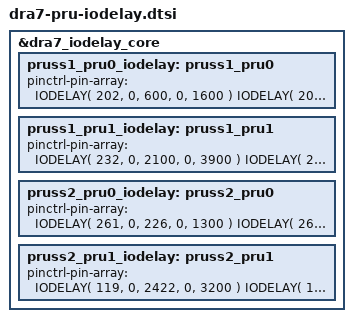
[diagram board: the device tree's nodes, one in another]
#define IODELAY_IN( index, a_delay, g_delay ) \
    ( 12 * (index) + 0 )   A_DELAY_PS( a_delay )   G_DELAY_PS( g_delay )
#define IODELAY_OUT( index, a_delay, g_delay ) \
    ( 12 * (index) + 4 )   A_DELAY_PS( a_delay )   G_DELAY_PS( g_delay ) \
    ( 12 * (index) + 8 )   A_DELAY_PS( a_delay )   G_DELAY_PS( g_delay )
#define IODELAY( index, in_a_delay, in_g_delay, out_a_delay, out_g_delay ) \
    IODELAY_IN( index, in_a_delay, in_g_delay ) \
    IODELAY_OUT( index, out_a_delay, out_g_delay )

&dra7_iodelay_core {
    pruss1_pru0_iodelay: pruss1_pru0 {
        pinctrl-pin-array = <
            IODELAY( 202, 0, 600, 0, 1600 ) // P19.52 AH6 core 0 gpio 0
            IODELAY( 203, 0, 0,   0, 2800 ) // P19.45 AH3 core 0 gpio 1
            IODELAY( 204, 0, 900, 0, 0    ) // P19.48 AH5 core 0 gpio 2
            IODELAY( 205, 0, 400, 0, 0    ) // P19.53 AH6 core 0 gpio 3
            IODELAY( 206, 0, 500, 0, 0    ) // P19.14 AH4 core 0 gpio 4
            IODELAY( 207, 0, 0,   0, 0    ) // P19.15 AG4 core 0 gpio 5
            IODELAY( 208, 0, 0,   0, 0    ) // x      AG2 core 0 gpio 6
            IODELAY( 186, 0, 0,   0, 600  ) // P19.46 AG3 core 0 gpio 7
            IODELAY( 187, 0, 300, 0, 0    ) // P19.49 AG5 core 0 gpio 8
            IODELAY( 188, 0, 800, 0, 2700 ) // P19.42 AF2 core 0 gpio 9
            IODELAY( 189, 0,   0, 0, 200  ) // x      AF6 core 0 gpio 10
            IODELAY( 190, 0, 600, 0, 800  ) // P19.43 AF3 core 0 gpio 11
            IODELAY( 191, 0,1100, 0, 0    ) // x      AF4 core 0 gpio 12
            IODELAY( 192, 0, 800, 0, 100  ) // P19.11 AF1 core 0 gpio 13
            IODELAY( 193, 0,1000, 0, 300  ) // x      AE3 core 0 gpio 14
            IODELAY( 194, 0,1100, 0, 0    ) // x      AE5 core 0 gpio 15
            IODELAY( 195, 0,2800, 0, 400  ) // P19.39 AE1 core 0 gpio 16
            IODELAY( 197, 0, 900, 0, 300  ) // P19.12 AE2 core 0 gpio 17
            IODELAY( 198, 0, 800, 0, 500  ) // x      AE6 core 0 gpio 18
            IODELAY( 199, 0,1400, 0, 0    ) // P19.40 AD2 core 0 gpio 19
            IODELAY( 200, 0,1001, 0, 500  ) // x      AD3 core 0 gpio 20
        >;
    };

    pruss1_pru1_iodelay: pruss1_pru1 {
        pinctrl-pin-array = <
            IODELAY( 232, 0, 2100, 0, 3900 ) // P18.42 E2 core 1 gpio 0
            IODELAY( 233, 0, 1000, 0, 5100 ) // P18.13 D2 core 1 gpio 1
            IODELAY( 234, 0, 1700, 0,    0 ) // P18.08 F4 core 1 gpio 2
            IODELAY( 235, 0, 700,  0, 2700 ) // P18.43 C1 core 1 gpio 3
            IODELAY( 236, 0, 1300, 0, 2600 ) // P18.39 E4 core 1 gpio 4
            IODELAY( 237, 0, 1700, 0, 2500 ) // P18.38 F5 core 1 gpio 5
            IODELAY( 238, 0, 1600, 0, 1900 ) // P18.07 E6 core 1 gpio 6
            IODELAY( 216, 0, 1600, 0, 1900 ) // P18.44 D3 core 1 gpio 7
            IODELAY( 217, 0, 1000, 0, 2700 ) // P18.06 F6 core 1 gpio 8
            IODELAY( 218, 0, 1400, 0, 3400 ) // eth1   D5 core 1 gpio 9
            IODELAY( 219, 0, 800,  0, 3200 ) // eth1   C2 core 1 gpio 10
            IODELAY( 220, 0, 0,    0, 3000 ) // eth1   C3 core 1 gpio 11
            IODELAY( 221, 0, 1600, 0, 2900 ) // eth1   C4 core 1 gpio 12
            IODELAY( 222, 0, 1200, 0, 2700 ) // eth1   B2 core 1 gpio 13
            IODELAY( 223, 0, 1500, 0, 3000 ) // eth1   D6 core 1 gpio 14
            IODELAY( 224, 0, 1000, 0, 2200 ) // eth1   C5 core 1 gpio 15
            IODELAY( 225, 0, 1100, 0, 2300 ) // eth1   A3 core 1 gpio 16
            IODELAY( 227, 0, 700,  0, 1800 ) // eth1   B3 core 1 gpio 17
            IODELAY( 228, 0, 1300, 0, 1900 ) // eth1   B4 core 1 gpio 18
            IODELAY( 229, 0, 1400, 0, 1400 ) // eth1   B5 core 1 gpio 19
            IODELAY( 230, 0, 1300, 0, 1900 ) // eth1   A4 core 1 gpio 20
        >;
    };

    pruss2_pru0_iodelay: pruss2_pru0 {
        pinctrl-pin-array = <
            IODELAY( 261, 0,  226, 0, 1300 ) // P18.26  G11 core 0 gpio 0
            IODELAY( 262, 0,    0, 0, 2500 ) // P18.48  E09 core 0 gpio 1
            IODELAY( 263, 0,  365, 0,  950 ) // P18.49  F09 core 0 gpio 2
            IODELAY( 264, 0,    0, 0,  800 ) // P18.45  F08 core 0 gpio 3
            IODELAY( 265, 0,  218, 0,  600 ) // P18.46  E07 core 0 gpio 4
            IODELAY( 266, 0,  186, 0,  500 ) // P18.47  E08 core 0 gpio 5
            IODELAY( 267, 0,  308, 0,  500 ) // P18.56  D09 core 0 gpio 6
            IODELAY( 245, 0,    0, 0,    0 ) // P18.16  D07 core 0 gpio 7
            IODELAY( 246, 0,  756, 0,  600 ) // P18.18  D08 core 0 gpio 8
            IODELAY( 247, 0,  531, 0, 2300 ) // P18.20  A05 core 0 gpio 9
            IODELAY( 248, 0,  180, 0,  450 ) // P18.15  C06 core 0 gpio 10
            IODELAY( 249, 0,  334, 0,  600 ) // P18.17  C08 core 0 gpio 11
            IODELAY( 250, 0, 1361, 0,  500 ) // P18.14  C07 core 0 gpio 12
            IODELAY( 251, 0,  488, 0,  100 ) // P18.50  B07 core 0 gpio 13
            IODELAY( 252, 0,  321, 0,  300 ) // P18.51  B08 core 0 gpio 14
            IODELAY( 253, 0,  254, 0,  700 ) // P18.21  A07 core 0 gpio 15
            IODELAY( 254, 0,  500, 0,  700 ) // P18.22  A08 core 0 gpio 16
            IODELAY( 256, 0,  716, 0,  900 ) // P18.19  C09 core 0 gpio 17
            IODELAY( 257, 0,    0, 0,  900 ) // P18.23  A09 core 0 gpio 18
            IODELAY( 258, 0,  404, 0,  300 ) // P18.52  B09 core 0 gpio 19
            IODELAY( 259, 0,  290, 0,  300 ) // P18.24  A10 core 0 gpio 20
        >;
    };

    pruss2_pru1_iodelay: pruss2_pru1 {
        pinctrl-pin-array = <
            IODELAY( 119, 0, 2422, 0, 3200 ) // ethmdio V01 core 1 gpio 0
            IODELAY( 118, 0, 3200, 0, 3900 ) // ethmdio U04 core 1 gpio 1
            IODELAY(   0, 0, 2100, 0, 2500 ) // x       U03 core 1 gpio 2
            IODELAY( 180, 0, 1900, 0, 3400 ) // P18.59  V02 core 1 gpio 3
            IODELAY( 181, 0, 1900, 0, 3000 ) // P18.29  Y01 core 1 gpio 4
            IODELAY( 150, 0, 2488, 0, 3300 ) // eth0    W09 core 1 gpio 5
            IODELAY( 151, 0, 2263, 0, 2700 ) // eth0    V09 core 1 gpio 6
            IODELAY( 155, 0, 2400, 0, 3200 ) // eth0    V07 core 1 gpio 7
            IODELAY( 154, 0, 2800, 0, 3000 ) // eth0    U07 core 1 gpio 8
            IODELAY( 153, 0, 2900, 0, 2500 ) // eth0    V06 core 1 gpio 9
            IODELAY( 152, 0, 2292, 0, 2900 ) // eth0    U06 core 1 gpio 10
            IODELAY( 144, 0, 1904, 0, 2600 ) // eth0    U05 core 1 gpio 11
            IODELAY( 145, 0, 3629, 0, 2800 ) // eth0    V05 core 1 gpio 12
            IODELAY( 149, 0, 3363, 0, 2700 ) // eth0    V04 core 1 gpio 13
            IODELAY( 148, 0, 2900, 0, 2600 ) // eth0    V03 core 1 gpio 14
            IODELAY( 147, 0, 3100, 0, 2700 ) // eth0    Y02 core 1 gpio 15
            IODELAY( 146, 0, 2800, 0, 2800 ) // eth0    W02 core 1 gpio 16
            IODELAY( 271, 0, 0,    0, 1200 ) // P18.28  E11 core 1 gpio 17
            IODELAY( 244, 0, 1020, 0, 600  ) // P18.25  F11 core 1 gpio 18
            IODELAY( 255, 0, 976,  0, 0    ) // P18.55  G10 core 1 gpio 19
            IODELAY( 260, 0, 946,  0, 300  ) // P18.54  F10 core 1 gpio 20
        >;
    };
};
